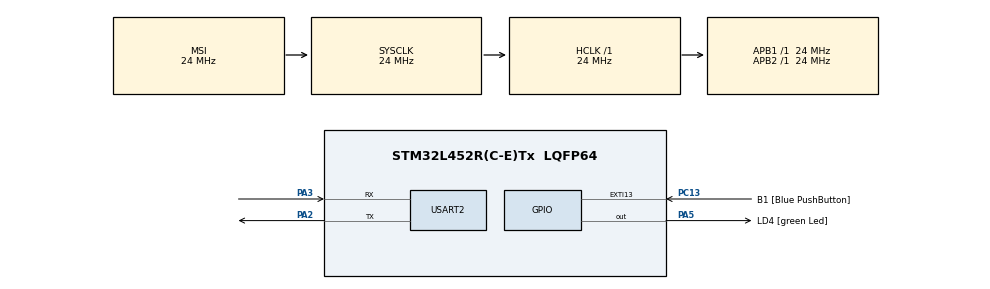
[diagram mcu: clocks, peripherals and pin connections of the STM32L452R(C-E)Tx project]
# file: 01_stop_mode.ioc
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LPTIM1.ClockPrescaler=LPTIM_PRESCALER_DIV16
Mcu.Family=STM32L4
Mcu.Name=STM32L452R(C-E)Tx
Mcu.Package=LQFP64
NVIC.PriorityGroup=NVIC_PRIORITYGROUP_4
NVIC.RTC_WKUP_IRQn=true\:0\:0\:false\:false\:true\:false\:true\:true\:true
NVIC.TIM6_DAC_IRQn=true\:15\:0\:false\:false\:true\:false\:false\:true\:true
NVIC.TimeBase=TIM6_DAC_IRQn
NVIC.TimeBaseIP=TIM6
PA13\ (JTMS/SWDIO).GPIO_Label=TMS
PA13\ (JTMS/SWDIO).Mode=Serial_Wire
PA13\ (JTMS/SWDIO).Signal=SYS_JTMS-SWDIO
PA14\ (JTCK/SWCLK).GPIO_Label=TCK
PA14\ (JTCK/SWCLK).Mode=Serial_Wire
PA14\ (JTCK/SWCLK).Signal=SYS_JTCK-SWCLK
PA2.Mode=Asynchronous
PA2.Signal=USART2_TX
PA3.Mode=Asynchronous
PA3.Signal=USART2_RX
PA5.GPIO_Label=LD4 [green Led]
PA5.GPIO_ModeDefaultOutputPP=GPIO_MODE_OUTPUT_PP
PA5.GPIO_PuPd=GPIO_NOPULL
PA5.GPIO_Speed=GPIO_SPEED_FREQ_LOW
PA5.Signal=GPIO_Output
PB3\ (JTDO/TRACESWO).GPIO_Label=SWO
PB3\ (JTDO/TRACESWO).Signal=SYS_JTDO-SWO
PC13.GPIO_Label=B1 [Blue PushButton]
PC13.GPIO_ModeDefaultEXTI=GPIO_MODE_IT_FALLING
PC13.GPIO_PuPd=GPIO_NOPULL
PC13.Signal=GPXTI13
PC14-OSC32_IN\ (PC14).Mode=LSE-External-Oscillator
PC14-OSC32_IN\ (PC14).Signal=RCC_OSC32_IN
PC15-OSC32_OUT\ (PC15).Mode=LSE-External-Oscillator
PC15-OSC32_OUT\ (PC15).Signal=RCC_OSC32_OUT
PH0-OSC_IN\ (PH0).Signal=RCC_OSC_IN
PH1-OSC_OUT\ (PH1).Signal=RCC_OSC_OUT
ProjectManager.HeapSize=0x200
ProjectManager.StackSize=0x400
ProjectManager.TargetToolchain=STM32CubeIDE
RCC.ADCFreq_Value=64000000
RCC.AHBFreq_Value=24000000
RCC.APB1Freq_Value=24000000
RCC.APB1TimFreq_Value=24000000
RCC.APB2Freq_Value=24000000
RCC.APB2TimFreq_Value=24000000
RCC.CortexFreq_Value=24000000
RCC.HCLKFreq_Value=24000000
RCC.HSE_VALUE=8000000
RCC.HSI48_VALUE=48000000
RCC.HSI_VALUE=16000000
RCC.LPTIM1CLockSelection=RCC_LPTIM1CLKSOURCE_LSE
RCC.LPTIM2CLockSelection=RCC_LPTIM2CLKSOURCE_LSE
RCC.MSIClockRange=RCC_MSIRANGE_9
RCC.MSI_VALUE=24000000
RCC.PLLN=10
RCC.PLLSourceVirtual=RCC_PLLSOURCE_HSI
RCC.PREFETCH_ENABLE=1
RCC.PWR_Regulator_Voltage_Scale=PWR_REGULATOR_VOLTAGE_SCALE2
RCC.SYSCLKFreq_VALUE=24000000
RCC.USBFreq_Value=64000000
RCC.VCOOutputFreq_Value=160000000
RTC.WakeUpCounter-WakeUp=0xffff
STMicroelectronics.X-CUBE-AZRTOS-L4.1.0.0.TX_ENABLE_EVENT_TRACE=1
STMicroelectronics.X-CUBE-AZRTOS-L4.1.0.0.TX_LOW_POWER=1
STMicroelectronics.X-CUBE-AZRTOS-L4.1.0.0.TX_LOW_POWER_TICKLESS=0
STMicroelectronics.X-CUBE-AZRTOS-L4.1.0.0.TX_LOW_POWER_TIMER_SETUP=App_ThreadX_LowPower_Timer_Setup
STMicroelectronics.X-CUBE-AZRTOS-L4.1.0.0.TX_LOW_POWER_USER_TIMER_ADJUST=App_ThreadX_LowPower_Timer_Adjust
STMicroelectronics.X-CUBE-AZRTOS-L4.1.0.0.ThreadXCcRTOSJjThreadXJjCore=true
STMicroelectronics.X-CUBE-AZRTOS-L4.1.0.0.ThreadXCcRTOSJjThreadXJjLowOoPowerOosupport=true
STMicroelectronics.X-CUBE-AZRTOS-L4.1.0.0.ThreadXCcRTOSJjThreadXJjTraceXOosupport=true
STMicroelectronics.X-CUBE-AZRTOS-L4.1.0.0_IsAnAzureRtosMw=true
USART2.VirtualMode-Asynchronous=VM_ASYNC
VP_LPTIM1_VS_LPTIM_counterModeInternalClock.Mode=Counts__internal_clock_event_00
VP_RTC_VS_RTC_Activate.Mode=RTC_Enabled
VP_RTC_VS_RTC_WakeUp_intern.Mode=WakeUp
VP_STMicroelectronics.X-CUBE-AZRTOS-L4_VS_RTOSJjThreadX_6.1.7_1.0.0.Mode=RTOSJjThreadX
VP_SYS_VS_tim6.Mode=TIM6
board=NUCLEO-L452RE

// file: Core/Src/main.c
/* USER CODE BEGIN Header */
/**
  ******************************************************************************
  * @file           : main.c
  * @brief          : Main program body
  ******************************************************************************
  *
  * Demostracion de como usar TreadX en bajo consumo. En el archivo
  * app_threadx.c esta la macro FM_THREADX_NO_LOW_POWER, hay que comentar esta
  * macro para que el uC ingrese a bajo consumo.
  * Esta aplicacion tambien corre TraceX, solo funciona si esta des-habilitado
  * el bajo consumo.
  *
  *
  *
  *
  ******************************************************************************
  */
/* USER CODE END Header */
#include "app_threadx.h"
#include "main.h"

LPTIM_HandleTypeDef hlptim1;

RTC_HandleTypeDef hrtc;

UART_HandleTypeDef huart2;

/* USER CODE BEGIN PV */
volatile uint8_t g_wait_in_low_power_flag = 0;

/* USER CODE END PV */

void SystemClock_Config(void);
static void MX_GPIO_Init(void);
static void MX_LPTIM1_Init(void);
static void MX_RTC_Init(void);
static void MX_USART2_UART_Init(void);

int main(void)
{

  /* MCU Configuration--------------------------------------------------------*/

  /* Reset of all peripherals, Initializes the Flash interface and the Systick. */
  HAL_Init();

  /* Configure the system clock */
  SystemClock_Config();

  /* Initialize all configured peripherals */
  MX_GPIO_Init();
  MX_LPTIM1_Init();
  MX_RTC_Init();
  MX_USART2_UART_Init();
  /* USER CODE BEGIN 2 */
  HAL_LPTIM_Counter_Start(&hlptim1, 0xffff);

  /* USER CODE END 2 */

  MX_ThreadX_Init();

  /* We should never get here as control is now taken by the scheduler */
  /* Infinite loop */
  while (1)
  {

  }
}

void SystemClock_Config(void)
{
  RCC_OscInitTypeDef RCC_OscInitStruct = {0};
  RCC_ClkInitTypeDef RCC_ClkInitStruct = {0};

  /** Configure the main internal regulator output voltage
  */
  if (HAL_PWREx_ControlVoltageScaling(PWR_REGULATOR_VOLTAGE_SCALE2) != HAL_OK)
  {
    Error_Handler();
  }

  /** Configure LSE Drive Capability
  */
  HAL_PWR_EnableBkUpAccess();
  __HAL_RCC_LSEDRIVE_CONFIG(RCC_LSEDRIVE_LOW);

  /** Initializes the RCC Oscillators according to the specified parameters
  * in the RCC_OscInitTypeDef structure.
  */
  RCC_OscInitStruct.OscillatorType = RCC_OSCILLATORTYPE_LSI|RCC_OSCILLATORTYPE_LSE
                              |RCC_OSCILLATORTYPE_MSI;
  RCC_OscInitStruct.LSEState = RCC_LSE_ON;
  RCC_OscInitStruct.LSIState = RCC_LSI_ON;
  RCC_OscInitStruct.MSIState = RCC_MSI_ON;
  RCC_OscInitStruct.MSICalibrationValue = 0;
  RCC_OscInitStruct.MSIClockRange = RCC_MSIRANGE_9;
  RCC_OscInitStruct.PLL.PLLState = RCC_PLL_NONE;
  if (HAL_RCC_OscConfig(&RCC_OscInitStruct) != HAL_OK)
  {
    Error_Handler();
  }

  /** Initializes the CPU, AHB and APB buses clocks
  */
  RCC_ClkInitStruct.ClockType = RCC_CLOCKTYPE_HCLK|RCC_CLOCKTYPE_SYSCLK
                              |RCC_CLOCKTYPE_PCLK1|RCC_CLOCKTYPE_PCLK2;
  RCC_ClkInitStruct.SYSCLKSource = RCC_SYSCLKSOURCE_MSI;
  RCC_ClkInitStruct.AHBCLKDivider = RCC_SYSCLK_DIV1;
  RCC_ClkInitStruct.APB1CLKDivider = RCC_HCLK_DIV1;
  RCC_ClkInitStruct.APB2CLKDivider = RCC_HCLK_DIV1;

  if (HAL_RCC_ClockConfig(&RCC_ClkInitStruct, FLASH_LATENCY_4) != HAL_OK)
  {
    Error_Handler();
  }

  /** Enable MSI Auto calibration
  */
  HAL_RCCEx_EnableMSIPLLMode();
}

static void MX_LPTIM1_Init(void)
{

  hlptim1.Instance = LPTIM1;
  hlptim1.Init.Clock.Source = LPTIM_CLOCKSOURCE_APBCLOCK_LPOSC;
  hlptim1.Init.Clock.Prescaler = LPTIM_PRESCALER_DIV16;
  hlptim1.Init.Trigger.Source = LPTIM_TRIGSOURCE_SOFTWARE;
  hlptim1.Init.OutputPolarity = LPTIM_OUTPUTPOLARITY_HIGH;
  hlptim1.Init.UpdateMode = LPTIM_UPDATE_IMMEDIATE;
  hlptim1.Init.CounterSource = LPTIM_COUNTERSOURCE_INTERNAL;
  hlptim1.Init.Input1Source = LPTIM_INPUT1SOURCE_GPIO;
  hlptim1.Init.Input2Source = LPTIM_INPUT2SOURCE_GPIO;
  if (HAL_LPTIM_Init(&hlptim1) != HAL_OK)
  {
    Error_Handler();
  }

}

static void MX_RTC_Init(void)
{

  /** Initialize RTC Only
  */
  hrtc.Instance = RTC;
  hrtc.Init.HourFormat = RTC_HOURFORMAT_24;
  hrtc.Init.AsynchPrediv = 127;
  hrtc.Init.SynchPrediv = 255;
  hrtc.Init.OutPut = RTC_OUTPUT_DISABLE;
  hrtc.Init.OutPutRemap = RTC_OUTPUT_REMAP_NONE;
  hrtc.Init.OutPutPolarity = RTC_OUTPUT_POLARITY_HIGH;
  hrtc.Init.OutPutType = RTC_OUTPUT_TYPE_OPENDRAIN;
  if (HAL_RTC_Init(&hrtc) != HAL_OK)
  {
    Error_Handler();
  }

  /** Enable the WakeUp
  */
  if (HAL_RTCEx_SetWakeUpTimer_IT(&hrtc, 0xffff, RTC_WAKEUPCLOCK_RTCCLK_DIV16) != HAL_OK)
  {
    Error_Handler();
  }

}

static void MX_USART2_UART_Init(void)
{

  huart2.Instance = USART2;
  huart2.Init.BaudRate = 115200;
  huart2.Init.WordLength = UART_WORDLENGTH_8B;
  huart2.Init.StopBits = UART_STOPBITS_1;
  huart2.Init.Parity = UART_PARITY_NONE;
  huart2.Init.Mode = UART_MODE_TX_RX;
  huart2.Init.HwFlowCtl = UART_HWCONTROL_NONE;
  huart2.Init.OverSampling = UART_OVERSAMPLING_16;
  huart2.Init.OneBitSampling = UART_ONE_BIT_SAMPLE_DISABLE;
  huart2.AdvancedInit.AdvFeatureInit = UART_ADVFEATURE_NO_INIT;
  if (HAL_UART_Init(&huart2) != HAL_OK)
  {
    Error_Handler();
  }

}

static void MX_GPIO_Init(void)
{
  GPIO_InitTypeDef GPIO_InitStruct = {0};

  /* GPIO Ports Clock Enable */
  __HAL_RCC_GPIOC_CLK_ENABLE();
  __HAL_RCC_GPIOH_CLK_ENABLE();
  __HAL_RCC_GPIOA_CLK_ENABLE();
  __HAL_RCC_GPIOB_CLK_ENABLE();

  /*Configure GPIO pin Output Level */
  HAL_GPIO_WritePin(LD4_GPIO_Port, LD4_Pin, GPIO_PIN_RESET);

  /*Configure GPIO pin : B1_Pin */
  GPIO_InitStruct.Pin = B1_Pin;
  GPIO_InitStruct.Mode = GPIO_MODE_IT_FALLING;
  GPIO_InitStruct.Pull = GPIO_NOPULL;
  HAL_GPIO_Init(B1_GPIO_Port, &GPIO_InitStruct);

  /*Configure GPIO pin : LD4_Pin */
  GPIO_InitStruct.Pin = LD4_Pin;
  GPIO_InitStruct.Mode = GPIO_MODE_OUTPUT_PP;
  GPIO_InitStruct.Pull = GPIO_NOPULL;
  GPIO_InitStruct.Speed = GPIO_SPEED_FREQ_LOW;
  HAL_GPIO_Init(LD4_GPIO_Port, &GPIO_InitStruct);

}

/* USER CODE BEGIN 4 */
__weak void HAL_RTCEx_WakeUpTimerEventCallback(RTC_HandleTypeDef *hrtc)
{
  /* Prevent unused argument(s) compilation warning */
  UNUSED(hrtc);
  HAL_RTCEx_DeactivateWakeUpTimer(hrtc);

  /* NOTE : This function should not be modified, when the callback is needed,
            the HAL_RTCEx_WakeUpTimerEventCallback could be implemented in the user file
   */
}

/* USER CODE END 4 */

void HAL_TIM_PeriodElapsedCallback(TIM_HandleTypeDef *htim)
{
  if (htim->Instance == TIM6) {
    HAL_IncTick();
  }
}

void Error_Handler(void)
{
  __disable_irq();
  while (1)
  {
  }
}
